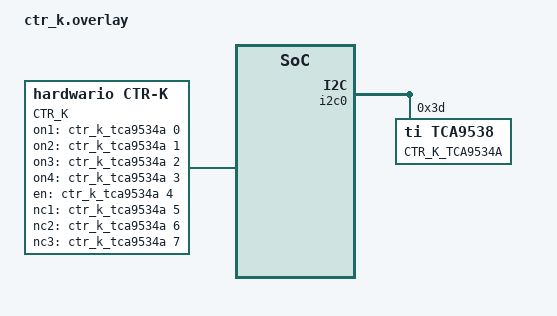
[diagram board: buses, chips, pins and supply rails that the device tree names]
/ {
	ctr_k: ctr_k {
		compatible = "hardwario,ctr-k";
		label = "CTR_K";
		status = "okay";
		on1-gpios = <&ctr_k_tca9534a 0 GPIO_ACTIVE_HIGH>;
		on2-gpios = <&ctr_k_tca9534a 1 GPIO_ACTIVE_HIGH>;
		on3-gpios = <&ctr_k_tca9534a 2 GPIO_ACTIVE_HIGH>;
		on4-gpios = <&ctr_k_tca9534a 3 GPIO_ACTIVE_HIGH>;
		en-gpios = <&ctr_k_tca9534a 4 GPIO_ACTIVE_HIGH>;
		nc1-gpios = <&ctr_k_tca9534a 5 GPIO_ACTIVE_HIGH>;
		nc2-gpios = <&ctr_k_tca9534a 6 GPIO_ACTIVE_HIGH>;
		nc3-gpios = <&ctr_k_tca9534a 7 GPIO_ACTIVE_HIGH>;
	};
};

&i2c0 {
	ctr_k_tca9534a: ctr_k_tca9534a@3d {
		compatible = "ti,tca9538";
		label = "CTR_K_TCA9534A";
		status = "okay";
		reg = <0x3d>;
		#gpio-cells = <2>;
		gpio-controller;
		ngpios = <8>;
	};
};
